# GD32W515Px register map
File version: 1.0
CPU: CM33 r0p0, little endian, MPU, FPU, 4 interrupt priority bits
Registers are 32-bit, read-write, reset 0x0 unless marked. A register's access mark holds for its fields unless they carry their own. Offsets are from the block's base; [hi:lo] are bit positions; {n}, {i} and the like mark numbered series; 'fields as' and 'values as' point back to an identical list.

## RTC — Real-time clock
Base 0x40002800
Same registers: SEC_RTC 0x50002800
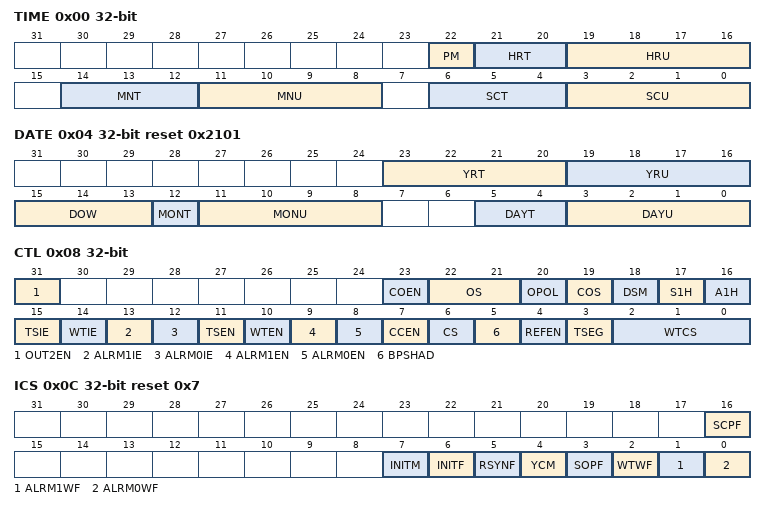
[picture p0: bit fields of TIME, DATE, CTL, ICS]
0x00 TIME
  [22] PM — AM/PM notation
  [21:20] HRT — Hour tens in BCD format
  [19:16] HRU — Hour units in BCD format
  [14:12] MNT — Minute tens in BCD format
  [11:8] MNU — Minute units in BCD format
  [6:4] SCT — Second tens in BCD format
  [3:0] SCU — Second units in BCD format
0x04 DATE reset 0x2101
  [23:20] YRT — Year tens in BCD code
  [19:16] YRU — Year units in BCD code
  [15:13] DOW — Days of the week
  [12] MONT — Month tens in BCD code
  [11:8] MONU — Month units in BCD code
  [5:4] DAYT — Date tens in BCD code
  [3:0] DAYU — Date units in BCD code
0x08 CTL access per field — control register
  [31] OUT2EN rw — RTC_OUT pin select
  [23] COEN rw — Calibration output enable
  [22:21] OS rw — Output selection
  [20] OPOL rw — Output polarity
  [19] COS rw — Calibration output selection
  [18] DSM rw — Daylight saving mark
  [17] S1H wo — Subtract 1 hour (winter time change)
  [16] A1H wo — Add 1 hour (summer time change)
  [15] TSIE rw — Time-stamp interrupt enable
  [14] WTIE rw — Auto-wakeup timer interrupt enable
  [13] ALRM1IE rw — RTC alarm-1 interrupt enable
  [12] ALRM0IE rw — RTC alarm-0 interrupt enable
  [11] TSEN rw — Time-stamp function enable
  [10] WTEN rw — Auto-wakeup timer function enable
  [9] ALRM1EN rw — Alarm-1 function enable
  [8] ALRM0EN rw — Alarm-0 function enable
  [7] CCEN rw — Coarse calibration function enable
  [6] CS rw — Clock System
  [5] BPSHAD rw — Shadow registers bypass control
  [4] REFEN rw — Reference clock detection function enable enable (50 or 60 Hz)
  [3] TSEG rw — Valid event edge of time-stamp
  [2:0] WTCS rw — Auto-wakeup timer clock selection
0x0C ICS access per field reset 0x7 — Initialization control and status register
  [16] SCPF ro — Smooth calibration pending flag
  [7] INITM rw — Enter initialization mode
  [6] INITF ro — Initialization state flag
  [5] RSYNF rw — Register synchronization flag
  [4] YCM ro — Year configuration mark
  [3] SOPF rw — Shift function operation pending flag
  [2] WTWF ro — Wakeup timer write enable flag
  [1] ALRM1WF ro — Alarm 1 configuration can be write flag
  [0] ALRM0WF ro — Alarm 0 configuration can be write flag
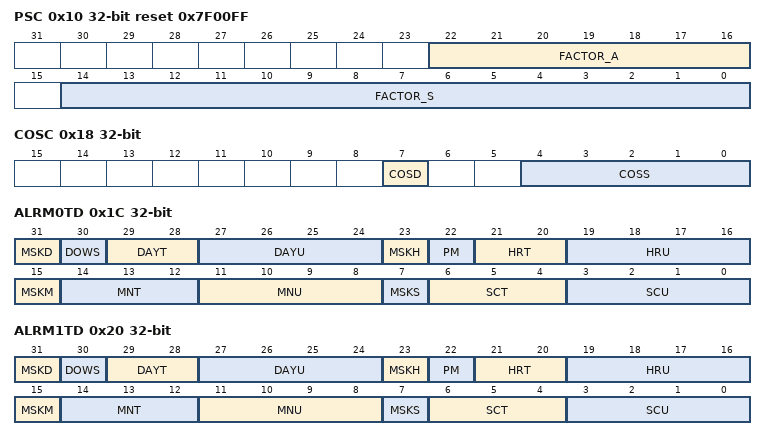
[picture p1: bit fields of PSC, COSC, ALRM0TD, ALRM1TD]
0x10 PSC reset 0x7F00FF — prescaler register
  [22:16] FACTOR_A — Asynchronous prescaler factor
  [14:0] FACTOR_S — Synchronous prescaler factor
0x14 WUT reset 0xFFFF — Wakeup timer register
  [15:0] WTRV — Auto-wakeup timer reloads value
0x18 COSC — Coarse calibration register
  [7] COSD — Coarse Calibration direction
  [4:0] COSS — Coarse Calibration step
0x1C ALRM0TD — Alarm 0 time and date register
  [31] MSKD — Alarm date mask bit
  [30] DOWS — Day of the week selected
  [29:28] DAYT — Date tens in BCD code.
  [27:24] DAYU — Date units or week day in BCD code.
  [23] MSKH — Alarm hours mask bit
  [22] PM — AM/PM flag
  [21:20] HRT — Hour tens in BCD code.
  [19:16] HRU — Hour units in BCD code.
  [15] MSKM — Alarm minutes mask bit
  [14:12] MNT — Minute tens in BCD code.
  [11:8] MNU — Minute units in BCD code.
  [7] MSKS — Alarm seconds mask bit
  [6:4] SCT — Second tens in BCD code.
  [3:0] SCU — Second units in BCD code.
0x20 ALRM1TD — Alarm 1 time and date register
  fields as ALRM0TD
0x24 WPK wo — write protection register
  [7:0] WPK — Write protection key
0x28 SS ro — sub second register
  [15:0] SSC — Sub second value
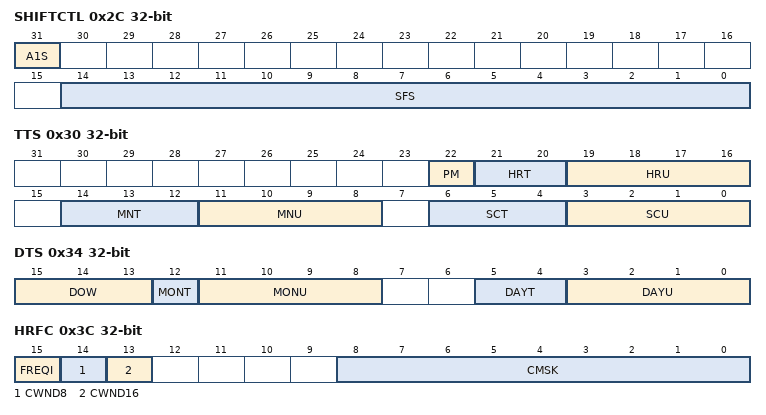
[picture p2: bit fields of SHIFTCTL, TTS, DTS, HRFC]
0x2C SHIFTCTL wo — shift function control register
  [31] A1S — One second add
  [14:0] SFS — Subtract a fraction of a second
0x30 TTS ro — Time of time stamp register
  [22] PM — AM/PM mark
  [21:20] HRT — Hour tens in BCD code.
  [19:16] HRU — Hour units in BCD code.
  [14:12] MNT — Minute tens in BCD code.
  [11:8] MNU — Minute units in BCD code.
  [6:4] SCT — Second tens in BCD code.
  [3:0] SCU — Second units in BCD code.
0x34 DTS ro — Date of time stamp register
  [15:13] DOW — Week day units
  [12] MONT — Month tens in BCD format
  [11:8] MONU — Month units in BCD format
  [5:4] DAYT — Date tens in BCD format
  [3:0] DAYU — Date units in BCD format
0x38 SSTS ro — Sub second of time stamp register
  [15:0] SSC — Sub second value
0x3C HRFC — calibration register
  [15] FREQI — Increase RTC frequency by 488.5PPM
  [14] CWND8 — Frequency compensation window 8 second selected
  [13] CWND16 — Frequency compensation window 16 second selected
  [8:0] CMSK — Calibration mask number
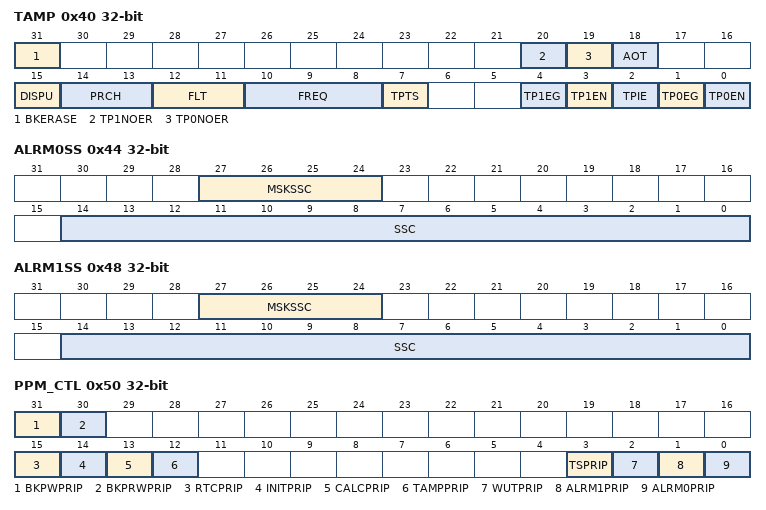
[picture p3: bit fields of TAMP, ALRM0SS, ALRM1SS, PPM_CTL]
0x40 TAMP — tamper and alternate function configuration register
  [31] BKERASE — Backup registers erase
  [20] TP1NOER — Tamper 1 no erase
  [19] TP0NOER — Tamper 0 no erase
  [18] AOT — RTC_ALARM Output Type
  [15] DISPU — RTC_TAMPx pull-up disable
  [14:13] PRCH — Pre-charge duration time of RTC_TAMPx
  [12:11] FLT — RTC_TAMPx filter count setting
  [10:8] FREQ — Sampling frequency of tamper event detection
  [7] TPTS — Make tamper function used for timestamp function
  [4] TP1EG — Tamper 1 event trigger edge
  [3] TP1EN — Tamper 1 detection enable
  [2] TPIE — Tamper detection interrupt enable
  [1] TP0EG — Tamper 0 event trigger edge
  [0] TP0EN — Tamper 0 detection enable
0x44 ALRM0SS — alarm A sub second register
  [27:24] MSKSSC — Mask control bit of SSC
  [14:0] SSC — Alarm sub second value
0x48 ALRM1SS — Alarm 1 sub second register
  fields as ALRM0SS
0x50 PPM_CTL — Privilege protection mode control register
  [31] BKPWPRIP — Backup registers zone B privilege protection
  [30] BKPRWPRIP — Backup registers zone A privilege protection
  [15] RTCPRIP — RTC privilege protection
  [14] INITPRIP — Initialization privilege protection
  [13] CALCPRIP — Shift register privilege protection
  [12] TAMPPRIP — Tamper privilege protection
  [3] TSPRIP — Timestamp privilege protection
  [2] WUTPRIP — Wakeup timer privilege protection
  [1] ALRM1PRIP — Alarm 1 privilege protection
  [0] ALRM0PRIP — Alarm 0 privilege protection
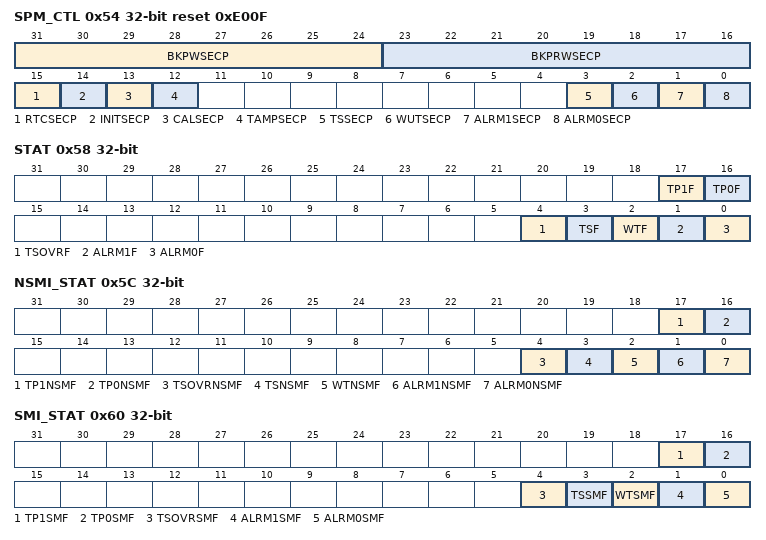
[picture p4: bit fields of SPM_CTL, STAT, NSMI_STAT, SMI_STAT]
0x54 SPM_CTL reset 0xE00F — Secure protection mode control register
  [31:24] BKPWSECP — Backup registers write protection offset
  [23:16] BKPRWSECP — Backup registers read/write protection offset
  [15] RTCSECP — RTC global protection
  [14] INITSECP — Initialization protection
  [13] CALSECP — Shift register, daylight saving, calibration and reference clock protection
  [12] TAMPSECP — Tamper protection
  [3] TSSECP — Timestamp protection
  [2] WUTSECP — Wakeup timer protection
  [1] ALRM1SECP — Alarm 1 protection
  [0] ALRM0SECP — Alarm 0 protection
0x58 STAT ro — Status register
  [17] TP1F — RTC_TAMP1 detected flag
  [16] TP0F — RTC_TAMP0 detected flag
  [4] TSOVRF — Time-stamp overflow flag
  [3] TSF — Time-stamp flag
  [2] WTF — Wakeup timer flag
  [1] ALRM1F — Alarm-1 occurs flag
  [0] ALRM0F — Alarm-0 occurs flag
0x5C NSMI_STAT — Non-secure masked interrupt status register
  [17] TP1NSMF — RTC_TAMP1 non-secure interrupt masked flag
  [16] TP0NSMF — RTC_TAMP0 non-secure interrupt masked flag
  [4] TSOVRNSMF — Time-stamp overflow non-secure masked flag
  [3] TSNSMF — Time-stamp flag
  [2] WTNSMF — Wakeup timer non-secure masked flag
  [1] ALRM1NSMF — Alarm-1 occurs non-secure masked flag
  [0] ALRM0NSMF — Alarm-0 occurs non-secure masked flag
0x60 SMI_STAT — Secure masked interrupt status register
  [17] TP1SMF — RTC_TAMP1 secure interrupt masked flag
  [16] TP0SMF — RTC_TAMP0 secure interrupt masked flag
  [4] TSOVRSMF — Time-stamp overflow secure masked flag
  [3] TSSMF — Time-stamp secure masked flag
  [2] WTSMF — Wakeup timer secure masked flag
  [1] ALRM1SMF — Alarm-1 occurs secure masked flag
  [0] ALRM0SMF — Alarm-0 occurs secure masked flag
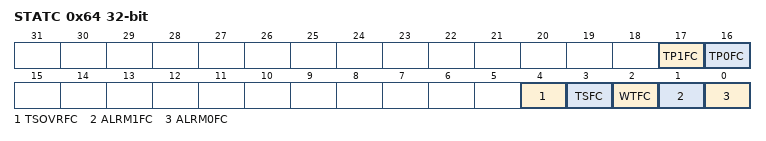
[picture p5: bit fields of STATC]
0x64 STATC wo — Status flag clear register
  [17] TP1FC — TAMP1 detection flag clear
  [16] TP0FC — TAMP0 detection flag clear
  [4] TSOVRFC — Timestamp overflow flag clear
  [3] TSFC — Timestamp flag clear
  [2] WTFC — Wakeup timer flag clear
  [1] ALRM1FC — Alarm 1 flag clear
  [0] ALRM0FC — Alarm 0 flag clear
{0x70+4i} BKP{i} (i=0..19) — backup register
  [31:0] DATA
